VERSION ""

NS_ :

BS_:

BU_: EXXOTEST__XXX

BO_ 277 trame_115: 4 EXXOTEST__XXX
 SG_ Direction_retro : 7|4@0+ (1.0000000,0.000000) [0.000000|1.000000] "" EXXOTEST__XXX
 SG_ Choix_retro : 3|4@0+ (1.0000000,0.000000) [0.000000|1.000000] "" EXXOTEST__XXX

BO_ 520 trame_208: 8 EXXOTEST__XXX
 SG_ regime_moteur : 7|8@0+ (32.0000000,0.000000) [0.000000|5000.000000] "tr/min" EXXOTEST__XXX

BO_ 543 trame_21F: 3 EXXOTEST__XXX
 SG_ Controle_radio : 7|8@0+ (1.0000000,0.000000) [0.000000|1.000000] "" EXXOTEST__XXX

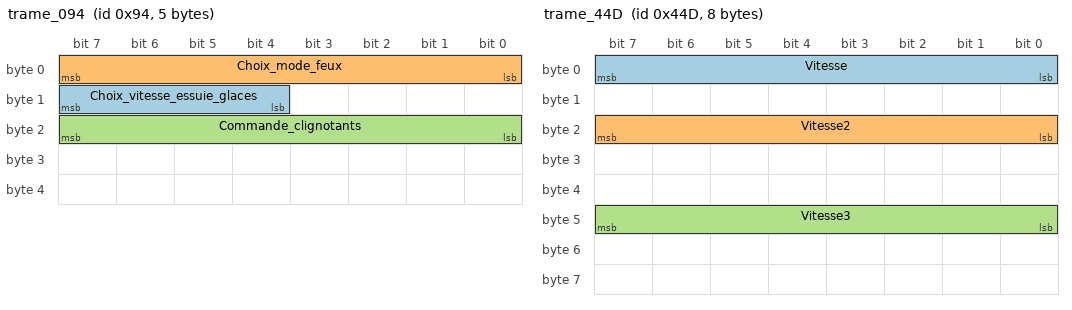
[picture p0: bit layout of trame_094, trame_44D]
BO_ 148 trame_094: 5 EXXOTEST__XXX
 SG_ Choix_vitesse_essuie_glaces : 15|4@0+ (1.0000000,0.000000) [0.000000|1.000000] "" EXXOTEST__XXX
 SG_ Choix_mode_feux : 7|8@0+ (1.0000000,0.000000) [0.000000|1.000000] "" EXXOTEST__XXX
 SG_ Commande_clignotants : 23|8@0+ (1.0000000,0.000000) [0.000000|1.000000] "" EXXOTEST__XXX

BO_ 1101 trame_44D: 8 EXXOTEST__XXX
 SG_ Vitesse : 7|8@0+ (5.0000000,0.000000) [0.000000|5000.000000] "km/h" EXXOTEST__XXX
 SG_ Vitesse2 : 23|8@0+ (5.0000000,0.000000) [0.000000|5000.000000] "km/h" EXXOTEST__XXX
 SG_ Vitesse3 : 47|8@0+ (5.0000000,0.000000) [0.000000|5000.000000] "km/h" EXXOTEST__XXX

VAL_ 277 Direction_retro 2 "haut" 1 "bas" 8 "droite" 4 "gauche" ;
VAL_ 277 Choix_retro 4 "retro_gauche" 2 "retro_droit" 0 "aucun" ;
VAL_ 543 Controle_radio 2 "SRC" 8 "Volume_plus" 4 "Volume_moins" 128 "Station_plus" 64 "Station_moins" ;
VAL_ 148 Choix_vitesse_essuie_glaces 0 "Vitesse0" 2 "Vitesse1" 4 "Vitesse2" 8 "Vitesse3" ;
VAL_ 148 Choix_mode_feux 32 "Repos" 64 "Feux_de_position" 128 "Feux_de_croisement" 152 "Feux_de_route" 40 "Appel_de_phare" 132 "Activation_antibrouillard" 130 "Desactivation_antibrouillard" ;
VAL_ 148 Commande_clignotants 0 "Desactive" 64 "Clignotant_droit" 128 "Clignotant_gauche" ;
